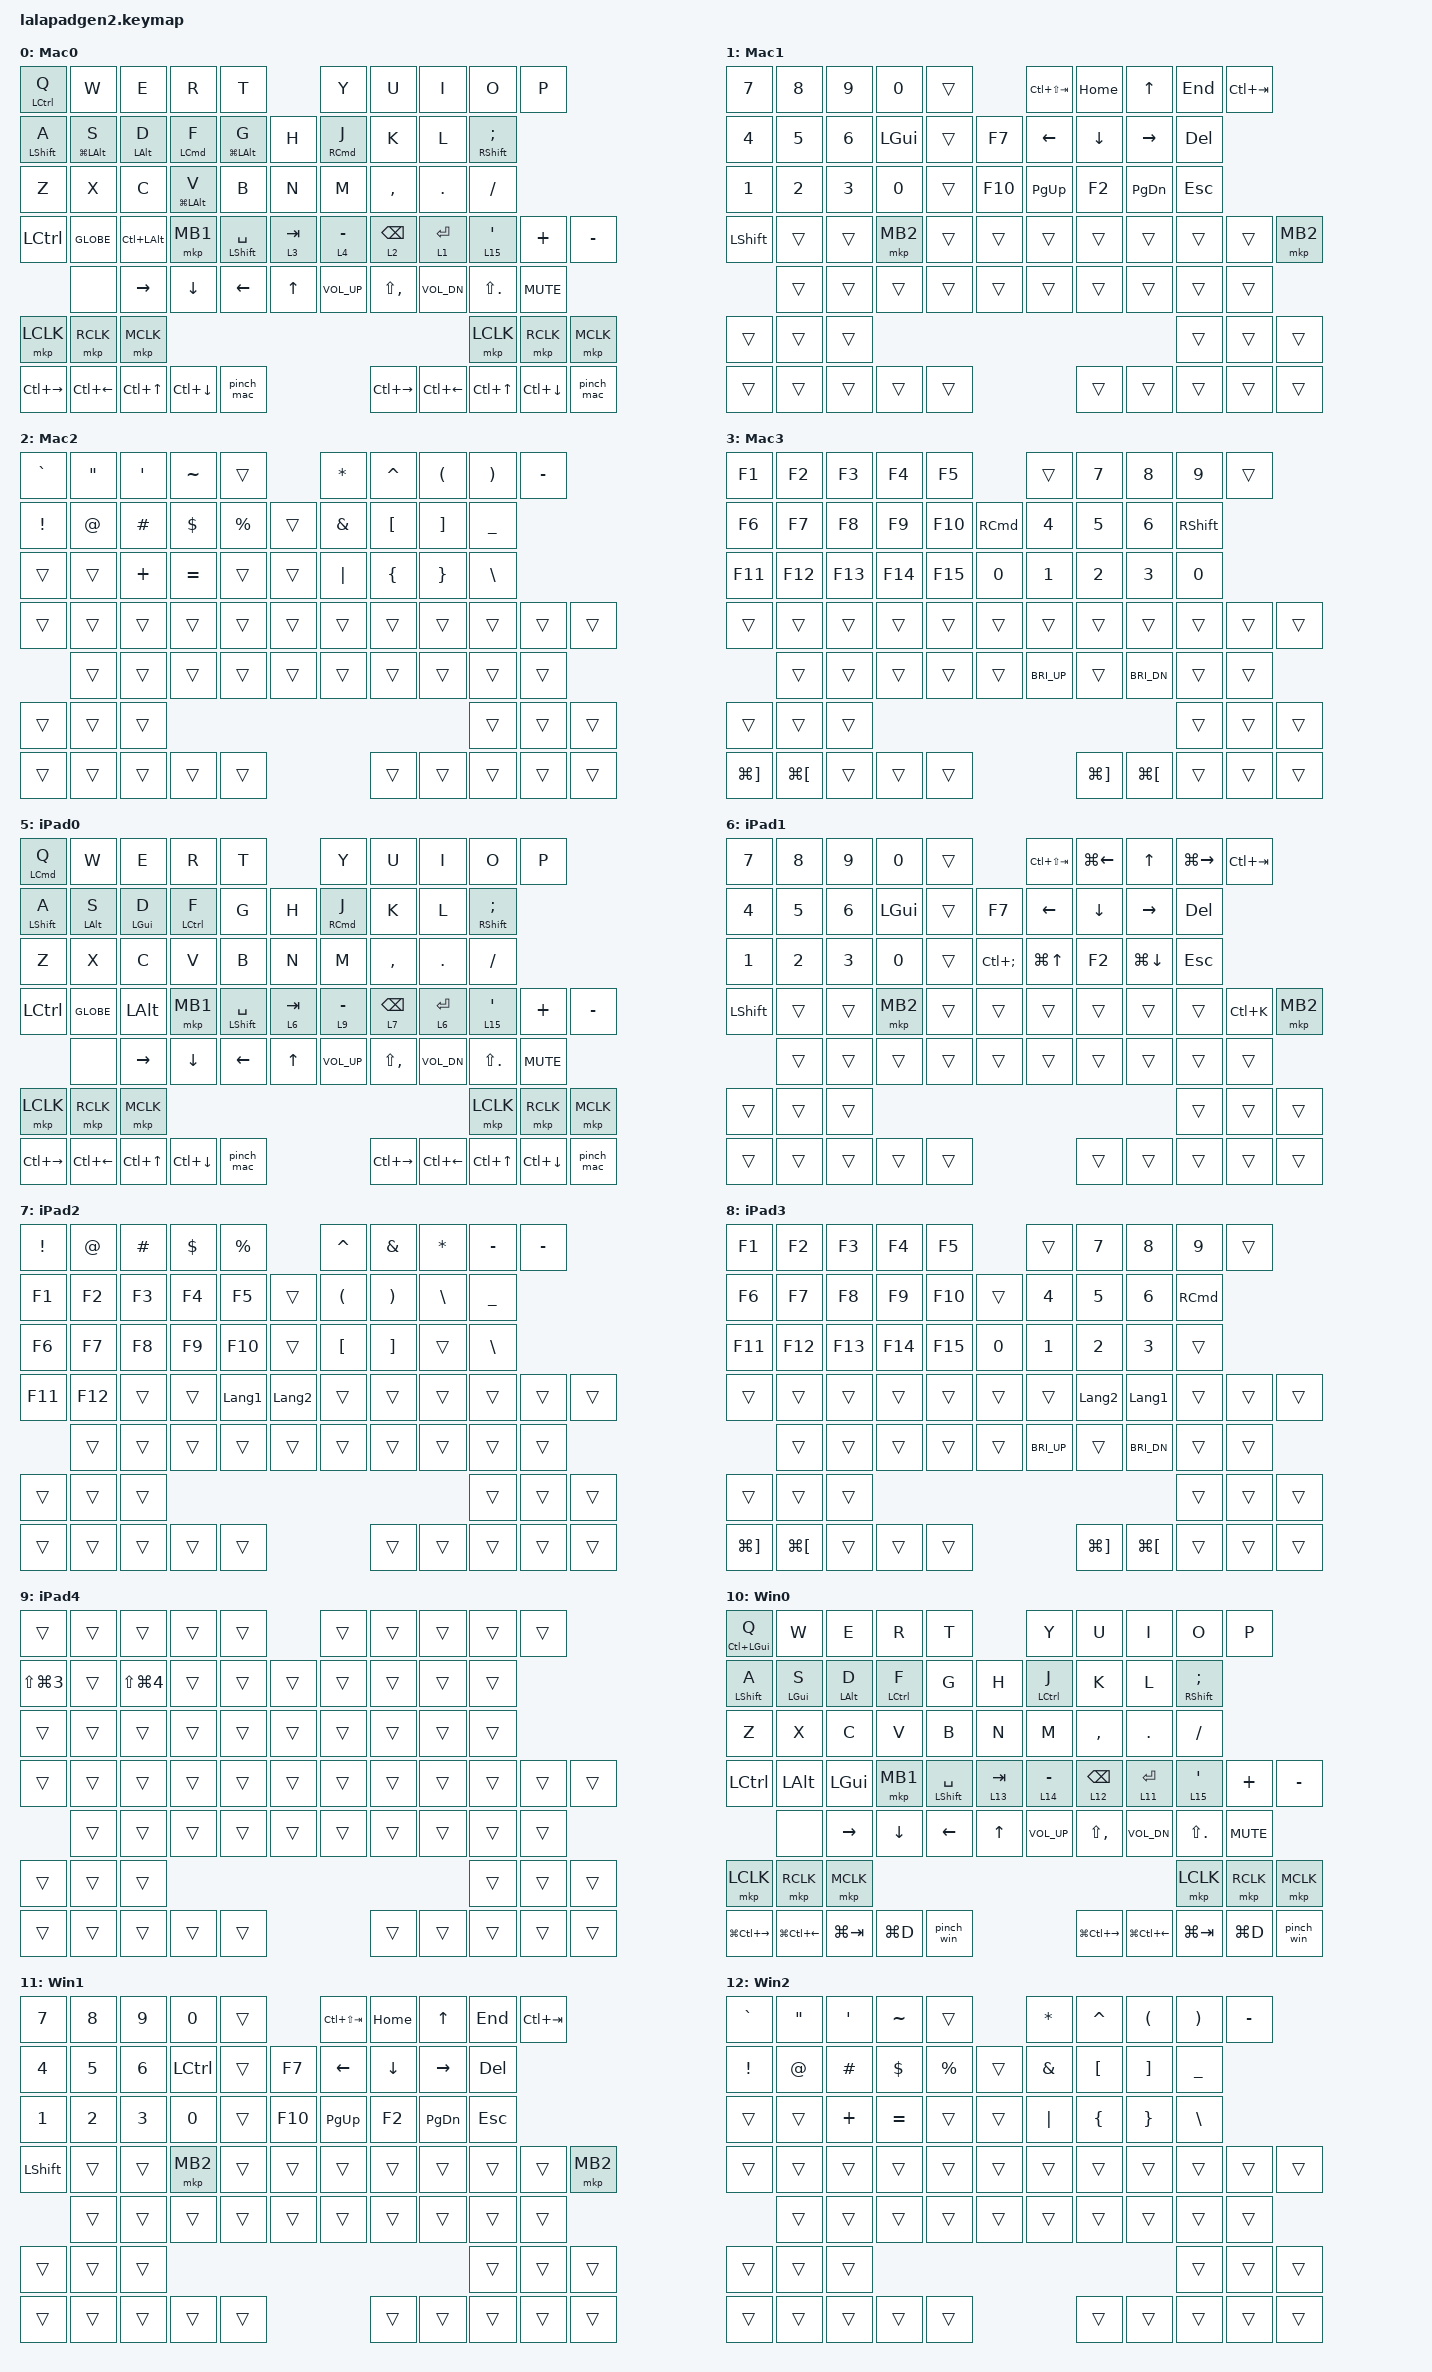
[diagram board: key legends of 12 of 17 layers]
#include <input/processors.dtsi>
#include <dt-bindings/zmk/zip_dynamic_scale.h>
#include <behaviors.dtsi>
#include <dt-bindings/zmk/bt.h>
#include <dt-bindings/zmk/keys.h>
#include <dt-bindings/zmk/outputs.h>
#include <dt-bindings/zmk/pointing.h>

&mt {
    flavor = "balanced";
    quick-tap-ms = <200>;
    tapping-term-ms = <180>;
    require-prior-idle-ms = <150>;
};

&lt {
    quick-tap-ms = <175>;
    tapping-term-ms = <165>;
};

/ {
    combos {
        compatible = "zmk,combos";

        alt_f4 {
            bindings = <&kp RA(F4)>;
            key-positions = <10 19>;
            timeout-ms = <201>;
            layers = <10>;
        };

        kana {
            bindings = <&kp LANG1>;
            key-positions = <16 17>;
            timeout-ms = <201>;
            layers = <10 0 5>;
        };

        ABC {
            bindings = <&kp LANG2>;
            key-positions = <12 13>;
            layers = <0 5 10>;
            timeout-ms = <201>;
        };
    };

    macros {
        Bluetooth0: Bluetooth0 {
            compatible = "zmk,behavior-macro";
            #binding-cells = <0>;
            bindings =
                <&bt BT_SEL 0 &to 0 &zip_dyn_scale_set ZDS_SC 2 &bt BT_DISC 1 &bt BT_DISC 2 &bt BT_DISC 3 &bt BT_DISC 4>,
                <&macro_press>;

            label = "BLUETOOTH0";
        };

        Bluetooth1: Bluetooth1 {
            compatible = "zmk,behavior-macro";
            #binding-cells = <0>;
            bindings =
                <&bt BT_SEL 1 &to 5 &zip_dyn_scale_set ZDS_SC 2 &bt BT_DISC 0 &bt BT_DISC 2 &bt BT_DISC 3 &bt BT_DISC 4>,
                <&macro_press>;

            label = "BLUETOOTH1";
        };

        Bluetooth2: Bluetooth2 {
            compatible = "zmk,behavior-macro";
            #binding-cells = <0>;
            bindings =
                <&bt BT_SEL 2 &to 10 &zip_dyn_scale_set ZDS_SC 40 &bt BT_DISC 0 &bt BT_DISC 1 &bt BT_DISC 3 &bt BT_DISC 4>,
                <&macro_press>;

            label = "BLUETOOTH2";
        };

        Bluetooth3: Bluetooth3 {
            compatible = "zmk,behavior-macro";
            #binding-cells = <0>;
            bindings =
                <&bt BT_SEL 3 &to 10 &zip_dyn_scale_set ZDS_SC 40 &bt BT_DISC 0 &bt BT_DISC 1 &bt BT_DISC 2 &bt BT_DISC 4>,
                <&macro_press>;

            label = "BLUETOOTH3";
        };

        Bluetooth4: Bluetooth4 {
            compatible = "zmk,behavior-macro";
            #binding-cells = <0>;
            bindings =
                <&bt BT_SEL 4 &to 10 &zip_dyn_scale_set ZDS_SC 40 &bt BT_DISC 0 &bt BT_DISC 1 &bt BT_DISC 2 &bt BT_DISC 3>,
                <&macro_press>;

            label = "BLUETOOTH4";
        };

        pinch_mac: pinch_mac {
            compatible = "zmk,behavior-macro";
            #binding-cells = <0>;
            bindings =
                <&macro_press>,
                <&mo 16 &kp LGUI>,
                <&macro_pause_for_release>,
                <&macro_release>,
                <&mo 16 &kp LGUI>;

            label = "PINCH_MAC";
        };

        pinch_win: pinch_win {
            compatible = "zmk,behavior-macro";
            #binding-cells = <0>;
            bindings =
                <&macro_press>,
                <&mo 16 &kp LCTRL>,
                <&macro_pause_for_release>,
                <&macro_release>,
                <&mo 16 &kp LCTRL>;

            label = "PINCH_WIN";
        };

        mac_sleep: mac_sleep {
            compatible = "zmk,behavior-macro";
            #binding-cells = <0>;
            wait-ms = <30>;
            tap-ms = <40>;
            bindings =
                <&macro_press>,
                <&kp LCTRL &kp LALT &kp LGUI>,
                <&macro_tap>,
                <&kp S>,
                <&macro_release>,
                <&kp LCTRL &kp LALT &kp LGUI>,
                <&macro_pause_for_release>;

            label = "MAC_SLEEP";
        };

        mac_shutdown: mac_shutdown {
            compatible = "zmk,behavior-macro";
            #binding-cells = <0>;
            wait-ms = <30>;
            tap-ms = <40>;
            bindings =
                <&macro_press>,
                <&kp LCTRL &kp LALT &kp LGUI>,
                <&macro_tap>,
                <&kp Q>,
                <&macro_release>,
                <&kp LCTRL &kp LALT &kp LGUI>,
                <&macro_pause_for_release>;

            label = "MAC_SHUTDOWN";
        };
    };

    behaviors {
        zip_dyn_scale: zip_dyn_scale {
            compatible = "zmk,behavior-zip-dynamic-scale";
            #binding-cells = <2>;
        };

        zip_dyn_scale_set: zip_dyn_scale_set {
            compatible = "zmk,behavior-zip-dynamic-scale-set";
            #binding-cells = <2>;
        };

        win_alt_d: win_alt_d {
            compatible = "zmk,behavior-hold-tap";
            #binding-cells = <2>;
            flavor = "balanced";
            tapping-term-ms = <200>;
            quick-tap-ms = <200>;
            require-prior-idle-ms = <150>;
            bindings = <&kp>, <&kp>;

            hold-trigger-key-positions = <6 7 8 13 16 17 18 23 35 37 38 52 53 54 55 56 57>;
            hold-trigger-on-release;
        };

        f_left_mod: f_left_mod {
            compatible = "zmk,behavior-hold-tap";
            #binding-cells = <2>;
            flavor = "balanced";
            tapping-term-ms = <200>;
            quick-tap-ms = <200>;
            require-prior-idle-ms = <150>;
            bindings = <&kp>, <&kp>;

            hold-trigger-key-positions = <5 6 7 8 9 15 16 17 18 19 25 26 27 28 29 34 37 38 41 52 53 54 55 56 57>;
            hold-trigger-on-release;
        };

        s_left_mod: s_left_mod {
            compatible = "zmk,behavior-hold-tap";
            #binding-cells = <2>;
            flavor = "balanced";
            tapping-term-ms = <200>;
            quick-tap-ms = <200>;
            require-prior-idle-ms = <150>;
            bindings = <&kp>, <&kp>;

            hold-trigger-key-positions = <5 6 7 8 9 15 16 17 18 19 25 26 27 28 29 34 37 38 41 52 53 54 55 56 57>;
            hold-trigger-on-release;
        };

        j_right_mod: j_right_mod {
            compatible = "zmk,behavior-hold-tap";
            #binding-cells = <2>;
            flavor = "balanced";
            tapping-term-ms = <200>;
            quick-tap-ms = <200>;
            require-prior-idle-ms = <150>;
            bindings = <&kp>, <&kp>;

            hold-trigger-key-positions = <0 1 2 3 4 10 11 12 13 14 17 18 20 21 22 23 24 30 31 32 33 34 35 39 52 53 54 55 56 57>;
            hold-trigger-on-release;
        };

        shift_space: shift_space {
            compatible = "zmk,behavior-hold-tap";
            #binding-cells = <2>;
            flavor = "balanced";
            tapping-term-ms = <165>;
            quick-tap-ms = <0>;
            require-prior-idle-ms = <60>;
            bindings = <&kp>, <&kp>;
        };

        shift_a: shift_a {
            compatible = "zmk,behavior-hold-tap";
            #binding-cells = <2>;
            flavor = "balanced";
            tapping-term-ms = <180>;
            quick-tap-ms = <0>;
            require-prior-idle-ms = <0>;
            bindings = <&kp>, <&kp>;

            hold-trigger-key-positions = <0 13 27 28 29 34 35 38 52 53 54 55 56 57>;
            #hold-trigger-on-release;
        };

        enter_lt: enter_layer_tap {
            compatible = "zmk,behavior-hold-tap";
            #binding-cells = <2>;
            flavor = "balanced";
            tapping-term-ms = <165>;
            quick-tap-ms = <175>;
            require-prior-idle-ms = <0>;
            bindings = <&mo>, <&kp>;

            hold-trigger-key-positions = <0 1 2 3 5 6 7 8 9 10 11 12 13 15 16 17 18 19 20 21 22 23 25 26 27 28 29 33>;
        };

        bksp_lt_hp: backspace_layer_tap_hold_preferred {
            compatible = "zmk,behavior-hold-tap";
            #binding-cells = <2>;
            flavor = "balanced";
            tapping-term-ms = <165>;
            quick-tap-ms = <175>;
            bindings = <&mo>, <&kp>;

            #hold-while-undecided;
        };
    };

    keymap {
        compatible = "zmk,keymap";

        Mac0 {
            display-name = "Mac0";
            bindings = <
&mt LEFT_CONTROL Q     &kp W         &kp E                  &kp R                       &kp T                                                          &kp Y                    &kp U                         &kp I                &kp O         &kp P
&shift_a LEFT_SHIFT A  &s_left_mod LG(LEFT_ALT) S  &win_alt_d LEFT_ALT D  &f_left_mod LEFT_COMMAND F  &s_left_mod LG(LEFT_ALT) G  &kp H  &j_right_mod RIGHT_COMMAND J  &kp K  &kp L  &mt RIGHT_SHIFT SEMICOLON
&kp Z                  &kp X         &kp C                  &s_left_mod LG(LEFT_ALT) V  &kp B                                                          &kp N                    &kp M                         &kp COMMA            &kp DOT       &kp SLASH
&kp LEFT_CONTROL  &kp GLOBE  &kp LC(LEFT_ALT)  &mkp MB1  &shift_space LEFT_SHIFT SPACE  &lt 3 TAB  &bksp_lt_hp 4 MINUS  &bksp_lt_hp 2 BACKSPACE  &enter_lt 1 ENTER  &lt 15 SINGLE_QUOTE  &kp PLUS  &kp MINUS
                       &none         &kp RIGHT              &kp DOWN                    &kp LEFT                       &kp UP     &kp C_VOL_UP         &kp LS(COMMA)            &kp C_VOL_DN                  &kp LS(DOT)          &kp C_MUTE
&mkp LCLK              &mkp RCLK     &mkp MCLK                                                                                                                                                                &mkp LCLK            &mkp RCLK     &mkp MCLK
&kp LC(RIGHT)          &kp LC(LEFT)  &kp LC(UP)             &kp LC(DOWN)                &pinch_mac                                                     &kp LC(RIGHT)            &kp LC(LEFT)                  &kp LC(UP)           &kp LC(DOWN)  &pinch_mac
            >;
        };

        Mac1 {
            display-name = "Mac1";
            bindings = <
&kp NUMBER_7    &kp NUMBER_8  &kp NUMBER_9  &kp NUMBER_0  &trans                  &kp LC(LS(TAB))  &kp HOME        &kp UP_ARROW    &kp END          &kp LC(TAB)
&kp NUMBER_4  &kp NUMBER_5  &kp NUMBER_6  &kp LEFT_GUI  &trans  &kp F7  &kp LEFT_ARROW  &kp DOWN_ARROW  &kp RIGHT_ARROW  &kp DELETE
&kp NUMBER_1    &kp NUMBER_2  &kp NUMBER_3  &kp NUMBER_0  &trans                  &kp F10          &kp PAGE_UP     &kp F2          &kp PAGE_DOWN    &kp ESCAPE
&kp LEFT_SHIFT  &trans  &trans  &mkp MB2  &trans  &trans  &trans  &trans  &trans  &trans  &trans  &mkp MB2
                &trans        &trans        &trans        &trans  &trans  &trans  &trans           &trans          &trans          &trans
&trans          &trans        &trans                                                                               &trans          &trans           &trans
&trans          &trans        &trans        &trans        &trans                  &trans           &trans          &trans          &trans           &trans
            >;
        };

        Mac2 {
            display-name = "Mac2";
            bindings = <
&kp GRAVE  &kp DOUBLE_QUOTES  &kp SINGLE_QUOTE  &kp TILDE  &trans  &kp ASTERISK  &kp CARET  &kp LEFT_PARENTHESIS  &kp RIGHT_PARENTHESIS  &kp MINUS
&kp EXCLAMATION  &kp AT_SIGN  &kp HASH  &kp DOLLAR  &kp PERCENT  &trans  &kp AMPERSAND  &kp LEFT_BRACKET  &kp RIGHT_BRACKET  &kp UNDERSCORE
&trans  &trans  &kp PLUS  &kp EQUAL  &trans  &trans  &kp PIPE  &kp LEFT_BRACE  &kp RIGHT_BRACE  &kp BACKSLASH
&trans           &trans             &trans            &trans      &trans       &trans  &trans  &trans        &trans         &trans                &trans                 &trans
                 &trans             &trans            &trans      &trans       &trans  &trans  &trans        &trans         &trans                &trans
&trans           &trans             &trans                                                                                  &trans                &trans                 &trans
&trans           &trans             &trans            &trans      &trans                       &trans        &trans         &trans                &trans                 &trans
            >;
        };

        Mac3 {
            display-name = "Mac3";
            bindings = <
&kp F1        &kp F2        &kp F3   &kp F4   &kp F5                         &trans             &kp NUMBER_7  &kp NUMBER_8  &kp NUMBER_9  &trans
&kp F6        &kp F7        &kp F8   &kp F9   &kp F10                        &kp RIGHT_COMMAND  &kp NUMBER_4  &kp NUMBER_5  &kp NUMBER_6  &kp RIGHT_SHIFT
&kp F11       &kp F12       &kp F13  &kp F14  &kp F15                        &kp NUMBER_0       &kp NUMBER_1  &kp NUMBER_2  &kp NUMBER_3  &kp N0
&trans        &trans        &trans   &trans   &trans   &trans  &trans        &trans             &trans        &trans        &trans        &trans
              &trans        &trans   &trans   &trans   &trans  &kp C_BRI_UP  &trans             &kp C_BRI_DN  &trans        &trans
&trans        &trans        &trans                                                                            &trans        &trans        &trans
&kp LG(RBKT)  &kp LG(LBKT)  &trans   &trans   &trans                         &kp LG(RBKT)       &kp LG(LBKT)  &trans        &trans        &trans
            >;
        };

        Mac4 {
            display-name = "Mac4";
            bindings = <
&trans          &trans              &trans          &trans              &trans                          &trans  &trans         &trans  &trans  &trans
&kp LS(LG(N3))  &kp LC(LS(LG(N3)))  &kp LS(LG(N4))  &kp LC(LS(LG(N4)))  &kp LS(LG(N5))                  &trans  &mac_shutdown  &trans  &trans  &trans
&kp LC(LG(Q))   &mac_sleep          &trans          &trans              &trans                          &trans  &trans         &trans  &trans  &trans
&trans          &trans              &trans          &trans              &trans          &trans  &trans  &trans  &trans         &trans  &trans  &trans
                &trans              &trans          &trans              &trans          &trans  &trans  &trans  &trans         &trans  &trans
&trans          &trans              &trans                                                                                     &trans  &trans  &trans
&trans          &trans              &trans          &trans              &trans                          &trans  &trans         &trans  &trans  &trans
            >;
        };

        iPad0 {
            display-name = "iPad0";
            bindings = <
&mt LEFT_COMMAND Q  &kp W         &kp E                  &kp R                &kp T                                                          &kp Y            &kp U                         &kp I                &kp O         &kp P
&mt LEFT_SHIFT A  &s_left_mod LEFT_ALT S  &win_alt_d LEFT_GUI D  &f_left_mod LCTRL F  &kp G  &kp H  &j_right_mod RIGHT_COMMAND J  &kp K  &kp L  &mt RIGHT_SHIFT SEMICOLON
&kp Z               &kp X         &kp C                  &kp V                &kp B                                                          &kp N            &kp M                         &kp COMMA            &kp DOT       &kp SLASH
&kp LEFT_CONTROL    &kp GLOBE     &kp LEFT_ALT           &mkp MB1             &shift_space LEFT_SHIFT SPACE  &lt 6 TAB  &bksp_lt_hp 9 MINUS  &lt 7 BACKSPACE  &lt 6 ENTER                   &lt 15 SINGLE_QUOTE  &kp PLUS      &kp MINUS
                    &none         &kp RIGHT              &kp DOWN             &kp LEFT                       &kp UP     &kp C_VOL_UP         &kp LS(COMMA)    &kp C_VOL_DN                  &kp LS(DOT)          &kp C_MUTE
&mkp LCLK           &mkp RCLK     &mkp MCLK                                                                                                                                                 &mkp LCLK            &mkp RCLK     &mkp MCLK
&kp LC(RIGHT)       &kp LC(LEFT)  &kp LC(UP)             &kp LC(DOWN)         &pinch_mac                                                     &kp LC(RIGHT)    &kp LC(LEFT)                  &kp LC(UP)           &kp LC(DOWN)  &pinch_mac
            >;
        };

        iPad1 {
            display-name = "iPad1";
            bindings = <
&kp NUMBER_7    &kp NUMBER_8  &kp NUMBER_9  &kp NUMBER_0  &trans                  &kp LC(LS(TAB))    &kp LG(LEFT)      &kp UP_ARROW    &kp LG(RIGHT)       &kp LC(TAB)
&kp NUMBER_4  &kp NUMBER_5  &kp NUMBER_6  &kp LEFT_GUI  &trans  &kp F7  &kp LEFT_ARROW  &kp DOWN_ARROW  &kp RIGHT_ARROW  &kp DELETE
&kp NUMBER_1    &kp NUMBER_2  &kp NUMBER_3  &kp NUMBER_0  &trans                  &kp LC(SEMICOLON)  &kp LG(UP_ARROW)  &kp F2          &kp LG(DOWN_ARROW)  &kp ESCAPE
&kp LEFT_SHIFT  &trans  &trans  &mkp MB2  &trans  &trans  &trans  &trans  &trans  &trans  &kp LC(K)  &mkp MB2
                &trans        &trans        &trans        &trans  &trans  &trans  &trans             &trans            &trans          &trans
&trans          &trans        &trans                                                                                   &trans          &trans              &trans
&trans          &trans        &trans        &trans        &trans                  &trans             &trans            &trans          &trans              &trans
            >;
        };

        iPad2 {
            display-name = "iPad2";
            bindings = <
&kp EXCLAMATION  &kp AT_SIGN  &kp HASH  &kp DOLLAR  &kp PERCENT  &kp CARET  &kp AMPERSAND  &kp ASTRK  &kp MINUS  &kp MINUS
&kp F1  &kp F2  &kp F3  &kp F4  &kp F5  &trans  &kp LEFT_PARENTHESIS  &kp RIGHT_PARENTHESIS  &kp BACKSLASH  &kp UNDERSCORE
&kp F6  &kp F7  &kp F8  &kp F9  &kp F10  &trans  &kp LEFT_BRACKET  &kp RIGHT_BRACKET  &trans  &kp BACKSLASH
&kp F11          &kp F12      &trans    &trans      &kp LANGUAGE_1  &kp LANGUAGE_2  &trans  &trans     &trans                &trans                 &trans         &trans
                 &trans       &trans    &trans      &trans          &trans          &trans  &trans     &trans                &trans                 &trans
&trans           &trans       &trans                                                                                         &trans                 &trans         &trans
&trans           &trans       &trans    &trans      &trans                                  &trans     &trans                &trans                 &trans         &trans
            >;
        };

        iPad3 {
            display-name = "iPad3";
            bindings = <
&kp F1        &kp F2        &kp F3   &kp F4   &kp F5                         &trans          &kp NUMBER_7    &kp NUMBER_8  &kp NUMBER_9  &trans
&kp F6        &kp F7        &kp F8   &kp F9   &kp F10                        &trans          &kp NUMBER_4    &kp NUMBER_5  &kp NUMBER_6  &kp RIGHT_COMMAND
&kp F11       &kp F12       &kp F13  &kp F14  &kp F15                        &kp NUMBER_0    &kp NUMBER_1    &kp NUMBER_2  &kp NUMBER_3  &trans
&trans        &trans        &trans   &trans   &trans   &trans  &trans        &kp LANGUAGE_2  &kp LANGUAGE_1  &trans        &trans        &trans
              &trans        &trans   &trans   &trans   &trans  &kp C_BRI_UP  &trans          &kp C_BRI_DN    &trans        &trans
&trans        &trans        &trans                                                                           &trans        &trans        &trans
&kp LG(RBKT)  &kp LG(LBKT)  &trans   &trans   &trans                         &kp LG(RBKT)    &kp LG(LBKT)    &trans        &trans        &trans
            >;
        };

        iPad4 {
            display-name = "iPad4";
            bindings = <
&trans          &trans  &trans          &trans  &trans                  &trans  &trans  &trans  &trans  &trans
&kp LS(LG(N3))  &trans  &kp LS(LG(N4))  &trans  &trans                  &trans  &trans  &trans  &trans  &trans
&trans          &trans  &trans          &trans  &trans                  &trans  &trans  &trans  &trans  &trans
&trans          &trans  &trans          &trans  &trans  &trans  &trans  &trans  &trans  &trans  &trans  &trans
                &trans  &trans          &trans  &trans  &trans  &trans  &trans  &trans  &trans  &trans
&trans          &trans  &trans                                                          &trans  &trans  &trans
&trans          &trans  &trans          &trans  &trans                  &trans  &trans  &trans  &trans  &trans
            >;
        };

        Windows0 {
            display-name = "Win0";
            bindings = <
&mt LC(LGUI) Q                  &kp W             &kp E                  &kp R                &kp T                                                            &kp Y                     &kp U                 &kp I                &kp O       &kp P
&shift_a LEFT_SHIFT A  &s_left_mod LEFT_GUI S  &win_alt_d LEFT_ALT D  &f_left_mod LCTRL F  &kp G  &kp H  &j_right_mod LCTRL J  &kp K  &kp L  &mt RIGHT_SHIFT SEMICOLON
&kp Z                  &kp X             &kp C                  &kp V                &kp B                                                            &kp N                     &kp M                 &kp COMMA            &kp DOT     &kp SLASH
&kp LEFT_CONTROL       &kp LEFT_ALT      &kp LEFT_GUI           &mkp MB1             &shift_space LEFT_SHIFT SPACE  &lt 13 TAB  &bksp_lt_hp 14 MINUS  &bksp_lt_hp 12 BACKSPACE  &enter_lt 11 ENTER    &lt 15 SINGLE_QUOTE  &kp PLUS    &kp MINUS
                       &none             &kp RIGHT              &kp DOWN             &kp LEFT                       &kp UP      &kp C_VOL_UP          &kp LS(COMMA)             &kp C_VOL_DN          &kp LS(DOT)          &kp C_MUTE
&mkp LCLK              &mkp RCLK         &mkp MCLK                                                                                                                                                    &mkp LCLK            &mkp RCLK   &mkp MCLK
&kp LG(LC(RIGHT))      &kp LG(LC(LEFT))  &kp LG(TAB)            &kp LG(D)            &pinch_win                                                       &kp LG(LC(RIGHT))         &kp LG(LC(LEFT))      &kp LG(TAB)          &kp LG(D)   &pinch_win
            >;
        };

        Windows1 {
            display-name = "Win1";
            bindings = <
&kp NUMBER_7    &kp NUMBER_8  &kp NUMBER_9  &kp NUMBER_0  &trans                  &kp LC(LS(TAB))  &kp HOME        &kp UP_ARROW    &kp END          &kp LC(TAB)
&kp NUMBER_4  &kp NUMBER_5  &kp NUMBER_6  &kp LCTRL  &trans  &kp F7  &kp LEFT_ARROW  &kp DOWN_ARROW  &kp RIGHT_ARROW  &kp DELETE
&kp NUMBER_1    &kp NUMBER_2  &kp NUMBER_3  &kp NUMBER_0  &trans                  &kp F10          &kp PAGE_UP     &kp F2          &kp PAGE_DOWN    &kp ESCAPE
&kp LEFT_SHIFT  &trans  &trans  &mkp MB2  &trans  &trans  &trans  &trans  &trans  &trans  &trans  &mkp MB2
                &trans        &trans        &trans        &trans  &trans  &trans  &trans           &trans          &trans          &trans
&trans          &trans        &trans                                                                               &trans          &trans           &trans
&trans          &trans        &trans        &trans        &trans                  &trans           &trans          &trans          &trans           &trans
            >;
        };

        Windows2 {
            display-name = "Win2";
            bindings = <
&kp GRAVE  &kp DOUBLE_QUOTES  &kp SINGLE_QUOTE  &kp TILDE  &trans  &kp ASTERISK  &kp CARET  &kp LEFT_PARENTHESIS  &kp RIGHT_PARENTHESIS  &kp MINUS
&kp EXCLAMATION  &kp AT_SIGN  &kp HASH  &kp DOLLAR  &kp PERCENT  &trans  &kp AMPERSAND  &kp LEFT_BRACKET  &kp RIGHT_BRACKET  &kp UNDERSCORE
&trans  &trans  &kp PLUS  &kp EQUAL  &trans  &trans  &kp PIPE  &kp LEFT_BRACE  &kp RIGHT_BRACE  &kp BACKSLASH
&trans           &trans             &trans            &trans      &trans       &trans  &trans  &trans        &trans         &trans                &trans                 &trans
                 &trans             &trans            &trans      &trans       &trans  &trans  &trans        &trans         &trans                &trans
&trans           &trans             &trans                                                                                  &trans                &trans                 &trans
&trans           &trans             &trans            &trans      &trans                       &trans        &trans         &trans                &trans                 &trans
            >;
        };

        Windows3 {
            display-name = "Win3";
            bindings = <
&kp F1    &kp F2    &kp F3   &kp F4   &kp F5                         &trans        &kp NUMBER_7  &kp NUMBER_8  &kp NUMBER_9  &trans
&kp F6    &kp F7    &kp F8   &kp F9   &kp F10                        &kp RCTRL     &kp NUMBER_4  &kp NUMBER_5  &kp NUMBER_6  &kp RIGHT_SHIFT
&kp F11   &kp F12   &kp F13  &kp F14  &kp F15                        &kp NUMBER_0  &kp NUMBER_1  &kp NUMBER_2  &kp NUMBER_3  &kp NUMBER_0
&trans    &trans    &trans   &trans   &trans   &trans  &trans        &trans        &trans        &trans        &trans        &trans
          &trans    &trans   &trans   &trans   &trans  &kp C_BRI_UP  &trans        &kp C_BRI_DN  &trans        &trans
&trans    &trans    &trans                                                                       &trans        &trans        &trans
&mkp MB5  &mkp MB4  &trans   &trans   &trans                         &mkp MB5      &mkp MB4      &trans        &trans        &trans
            >;
        };

        Windows4 {
            display-name = "Windows4";
            bindings = <
&trans     &trans       &trans  &trans         &trans                  &trans  &trans       &trans  &trans  &trans
&trans     &trans       &trans  &kp LG(LS(S))  &trans                  &trans  &kp C_POWER  &trans  &trans  &trans
&kp LG(L)  &kp C_SLEEP  &trans  &trans         &trans                  &trans  &trans       &trans  &trans  &trans
&trans     &trans       &trans  &trans         &trans  &trans  &trans  &trans  &trans       &trans  &trans  &trans
           &trans       &trans  &trans         &trans  &trans  &trans  &trans  &trans       &trans  &trans
&trans     &trans       &trans                                                              &trans  &trans  &trans
&trans     &trans       &trans  &trans         &trans                  &trans  &trans       &trans  &trans  &trans
            >;
        };

        Bluetooth {
            display-name = "BT";
            bindings = <
&out OUT_TOG                   &trans                         &trans                         &trans                         &trans                                          &trans  &trans       &trans       &trans       &Bluetooth4
&zip_dyn_scale ZDS_XY ZDS_INC  &zip_dyn_scale ZDS_XY ZDS_DEC  &zip_dyn_scale ZDS_SC ZDS_INC  &zip_dyn_scale ZDS_SC ZDS_DEC  &zip_dyn_scale ZDS_ALL ZDS_RST                  &trans  &Bluetooth0  &Bluetooth1  &Bluetooth2  &Bluetooth3
&trans                         &trans                         &trans                         &trans                         &trans                                          &trans  &trans       &trans       &trans       &bt BT_CLR
&trans                         &trans                         &trans                         &trans                         &trans                          &trans  &trans  &trans  &trans       &trans       &bootloader  &bt BT_CLR_ALL
                               &trans                         &trans                         &trans                         &trans                          &trans  &trans  &trans  &trans       &trans       &trans
&trans                         &trans                         &trans                                                                                                                             &trans       &trans       &trans
&trans                         &trans                         &trans                         &trans                         &trans                                          &trans  &trans       &trans       &trans       &trans
            >;
        };

        Pinch {
            display-name = "Pinch";
            bindings = <
&trans  &trans  &trans  &trans  &trans                  &trans  &trans  &trans  &trans  &trans
&trans  &trans  &trans  &trans  &trans                  &trans  &trans  &trans  &trans  &trans
&trans  &trans  &trans  &trans  &trans                  &trans  &trans  &trans  &trans  &trans
&trans  &trans  &trans  &trans  &trans  &trans  &trans  &trans  &trans  &trans  &trans  &trans
        &trans  &trans  &trans  &trans  &trans  &trans  &trans  &trans  &trans  &trans
&trans  &trans  &trans                                                  &trans  &trans  &trans
&trans  &trans  &trans  &trans  &trans                  &trans  &trans  &trans  &trans  &trans
            >;
        };
    };
};
